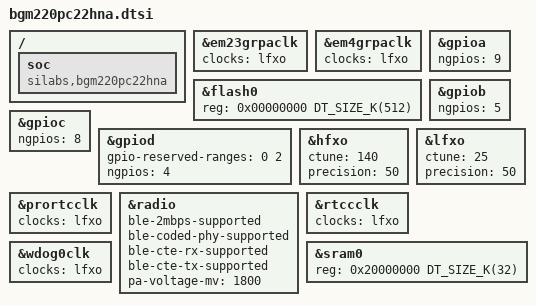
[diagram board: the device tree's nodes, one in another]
/*
 * Copyright (c) 2025 Silicon Laboratories Inc.
 *
 * SPDX-License-Identifier: Apache-2.0
 */

#include <mem.h>
#include <silabs/xg22/bgm22.dtsi>

/ {
	soc {
		compatible = "silabs,bgm220pc22hna", "silabs,bgm22", "silabs,xg22", "silabs,efr32",
			     "simple-bus";
	};
};

&em23grpaclk {
	clocks = <&lfxo>;
};

&em4grpaclk {
	clocks = <&lfxo>;
};

&flash0 {
	reg = <0x00000000 DT_SIZE_K(512)>;
};

&gpioa {
	ngpios = <9>;
};

&gpiob {
	ngpios = <5>;
};

&gpioc {
	ngpios = <8>;
};

&gpiod {
	gpio-reserved-ranges = <0 2>;
	ngpios = <4>;
};

&hfxo {
	ctune = <140>;
	precision = <50>;
	status = "okay";
};

&lfxo {
	ctune = <25>;
	precision = <50>;
	status = "okay";
};

&prortcclk {
	clocks = <&lfxo>;
};

&radio {
	ble-2mbps-supported;
	ble-coded-phy-supported;
	ble-cte-rx-supported;
	ble-cte-tx-supported;
	pa-voltage-mv = <1800>;
};

&rtccclk {
	clocks = <&lfxo>;
};

&sram0 {
	reg = <0x20000000 DT_SIZE_K(32)>;
};

&wdog0clk {
	clocks = <&lfxo>;
};
